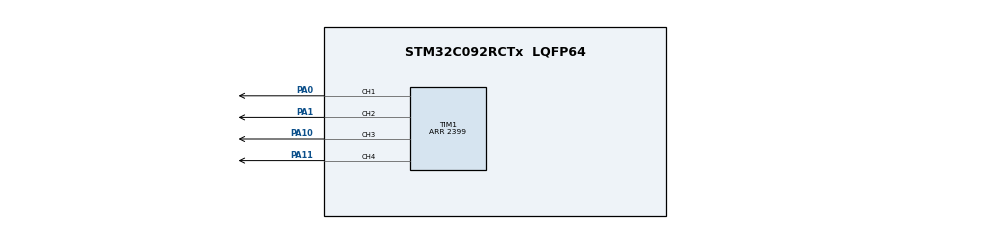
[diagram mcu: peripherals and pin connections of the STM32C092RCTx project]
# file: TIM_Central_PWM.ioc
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Mcu.Family=STM32C0
Mcu.Name=STM32C092RCTx
Mcu.Package=LQFP64
PA0.GPIO_PuPd=GPIO_PULLDOWN
PA0.GPIO_Speed=GPIO_SPEED_FREQ_HIGH
PA0.Signal=S_TIM1_CH1
PA1.GPIO_PuPd=GPIO_PULLDOWN
PA1.GPIO_Speed=GPIO_SPEED_FREQ_HIGH
PA1.Signal=S_TIM1_CH2
PA10.GPIO_PuPd=GPIO_PULLDOWN
PA10.GPIO_Speed=GPIO_SPEED_FREQ_HIGH
PA10.Signal=S_TIM1_CH3
PA11\ [PA9].GPIO_PuPd=GPIO_PULLDOWN
PA11\ [PA9].GPIO_Speed=GPIO_SPEED_FREQ_HIGH
PA11\ [PA9].Signal=S_TIM1_CH4
ProjectManager.HeapSize=0x200
ProjectManager.StackSize=0x400
ProjectManager.TargetToolchain=EWARM V9.20
RCC.ADCFreq_Value=48000000
RCC.AHBFreq_Value=48000000
RCC.CortexFreq_Value=48000000
RCC.EXTERNAL_CLOCK_VALUE=12288000
RCC.HCLKFreq_Value=48000000
RCC.HSE_VALUE=8000000
RCC.HSISYSCLKDivider=RCC_HSI_DIV1
RCC.HSI_VALUE=48000000
RCC.LSE_VALUE=32768
RCC.SYSCLKFreq_VALUE=48000000
SH.S_TIM1_CH1.0=TIM1_CH1,PWM Generation1 CH1
SH.S_TIM1_CH2.0=TIM1_CH2,PWM Generation2 CH2
SH.S_TIM1_CH3.0=TIM1_CH3,PWM Generation3 CH3
SH.S_TIM1_CH4.0=TIM1_CH4,PWM Generation4 CH4
TIM1.Channel-PWM\ Generation1\ CH1=TIM_CHANNEL_1
TIM1.Channel-PWM\ Generation2\ CH2=TIM_CHANNEL_2
TIM1.Channel-PWM\ Generation3\ CH3=TIM_CHANNEL_3
TIM1.Channel-PWM\ Generation4\ CH4=TIM_CHANNEL_4
TIM1.CounterMode=TIM_COUNTERMODE_CENTERALIGNED1
TIM1.OCMode_PWM-PWM\ Generation4\ CH4=TIM_OCMODE_PWM2
TIM1.Period=2399
TIM1.Pulse-PWM\ Generation1\ CH1=599
TIM1.Pulse-PWM\ Generation2\ CH2=1199
TIM1.Pulse-PWM\ Generation3\ CH3=1799
TIM1.Pulse-PWM\ Generation4\ CH4=2351
TIM1.TIM_MasterOutputTrigger2=TIM_TRGO2_OC4REF
VP_TIM1_VS_ClockSourceINT.Mode=Internal
board=custom

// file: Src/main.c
/* USER CODE BEGIN Header */
/**
  ******************************************************************************
  * @file           : main.c
  * @brief          : Main program body
  ******************************************************************************
  * @attention
  *
  * Copyright (c) 2024 STMicroelectronics.
  * All rights reserved.
  *
  * This software is licensed under terms that can be found in the LICENSE file
  * in the root directory of this software component.
  * If no LICENSE file comes with this software, it is provided AS-IS.
  *
  ******************************************************************************
  */
/* USER CODE END Header */
#include "main.h"

void SystemClock_Config(void);
static void MX_GPIO_Init(void);
static void MX_TIM1_Init(void);

int main(void)
{

  /* MCU Configuration--------------------------------------------------------*/

  /* Reset of all peripherals, Initializes the Flash interface and the Systick. */
  LL_APB2_GRP1_EnableClock(LL_APB2_GRP1_PERIPH_SYSCFG);
  LL_APB1_GRP1_EnableClock(LL_APB1_GRP1_PERIPH_PWR);

  /* SysTick_IRQn interrupt configuration */
  NVIC_SetPriority(SysTick_IRQn, 3);

  /* Configure the system clock */
  SystemClock_Config();

  /* Initialize all configured peripherals */
  MX_GPIO_Init();
  MX_TIM1_Init();
  /* USER CODE BEGIN 2 */

  /**********************************/
  /* Start output signal generation */
  /**********************************/
  /* Enable output channels 1, 2, 3 and 4 */
  LL_TIM_CC_EnableChannel(TIM1, LL_TIM_CHANNEL_CH1 | LL_TIM_CHANNEL_CH2 | LL_TIM_CHANNEL_CH3 | LL_TIM_CHANNEL_CH4);

  /* Enable counter */
  LL_TIM_EnableCounter(TIM1);
  /* USER CODE END 2 */

  /* Infinite loop */
  while (1)
  {

  }
}

void SystemClock_Config(void)
{

  LL_FLASH_SetLatency(LL_FLASH_LATENCY_1);

  /* HSI configuration and activation */
  LL_RCC_HSI_Enable();
  while(LL_RCC_HSI_IsReady() != 1)
  {
  }

  LL_RCC_HSI_SetCalibTrimming(64);
  LL_RCC_SetHSIDiv(LL_RCC_HSI_DIV_1);
  /* Set AHB prescaler*/
  LL_RCC_SetAHBPrescaler(LL_RCC_HCLK_DIV_1);

  LL_RCC_SetSYSDivider(LL_RCC_SYSCLK_DIV_1);
  /* Sysclk activation on the HSI */
  LL_RCC_SetSysClkSource(LL_RCC_SYS_CLKSOURCE_HSI);
  while(LL_RCC_GetSysClkSource() != LL_RCC_SYS_CLKSOURCE_STATUS_HSI)
  {
  }

  /* Set APB1 prescaler*/
  LL_RCC_SetAPB1Prescaler(LL_RCC_APB1_DIV_1);
  LL_Init1msTick(48000000);
  /* Update CMSIS variable (which can be updated also through SystemCoreClockUpdate function) */
  LL_SetSystemCoreClock(48000000);
}

static void MX_TIM1_Init(void)
{

  LL_TIM_InitTypeDef TIM_InitStruct = {0};
  LL_TIM_OC_InitTypeDef TIM_OC_InitStruct = {0};
  LL_TIM_BDTR_InitTypeDef TIM_BDTRInitStruct = {0};

  LL_GPIO_InitTypeDef GPIO_InitStruct = {0};

  /* Peripheral clock enable */
  LL_APB2_GRP1_EnableClock(LL_APB2_GRP1_PERIPH_TIM1);

  TIM_InitStruct.Prescaler = 0;
  TIM_InitStruct.CounterMode = LL_TIM_COUNTERMODE_CENTER_DOWN;
  TIM_InitStruct.Autoreload = 2399;
  TIM_InitStruct.ClockDivision = LL_TIM_CLOCKDIVISION_DIV1;
  TIM_InitStruct.RepetitionCounter = 0;
  LL_TIM_Init(TIM1, &TIM_InitStruct);
  LL_TIM_DisableARRPreload(TIM1);
  LL_TIM_SetClockSource(TIM1, LL_TIM_CLOCKSOURCE_INTERNAL);
  LL_TIM_OC_EnablePreload(TIM1, LL_TIM_CHANNEL_CH1);
  TIM_OC_InitStruct.OCMode = LL_TIM_OCMODE_PWM1;
  TIM_OC_InitStruct.OCState = LL_TIM_OCSTATE_DISABLE;
  TIM_OC_InitStruct.OCNState = LL_TIM_OCSTATE_DISABLE;
  TIM_OC_InitStruct.CompareValue = 599;
  TIM_OC_InitStruct.OCPolarity = LL_TIM_OCPOLARITY_HIGH;
  TIM_OC_InitStruct.OCNPolarity = LL_TIM_OCPOLARITY_HIGH;
  TIM_OC_InitStruct.OCIdleState = LL_TIM_OCIDLESTATE_LOW;
  TIM_OC_InitStruct.OCNIdleState = LL_TIM_OCIDLESTATE_LOW;
  LL_TIM_OC_Init(TIM1, LL_TIM_CHANNEL_CH1, &TIM_OC_InitStruct);
  LL_TIM_OC_DisableFast(TIM1, LL_TIM_CHANNEL_CH1);
  LL_TIM_OC_EnablePreload(TIM1, LL_TIM_CHANNEL_CH2);
  TIM_OC_InitStruct.CompareValue = 1199;
  LL_TIM_OC_Init(TIM1, LL_TIM_CHANNEL_CH2, &TIM_OC_InitStruct);
  LL_TIM_OC_DisableFast(TIM1, LL_TIM_CHANNEL_CH2);
  LL_TIM_OC_EnablePreload(TIM1, LL_TIM_CHANNEL_CH3);
  TIM_OC_InitStruct.CompareValue = 1799;
  LL_TIM_OC_Init(TIM1, LL_TIM_CHANNEL_CH3, &TIM_OC_InitStruct);
  LL_TIM_OC_DisableFast(TIM1, LL_TIM_CHANNEL_CH3);
  LL_TIM_OC_EnablePreload(TIM1, LL_TIM_CHANNEL_CH4);
  TIM_OC_InitStruct.OCMode = LL_TIM_OCMODE_PWM2;
  TIM_OC_InitStruct.CompareValue = 2351;
  LL_TIM_OC_Init(TIM1, LL_TIM_CHANNEL_CH4, &TIM_OC_InitStruct);
  LL_TIM_OC_DisableFast(TIM1, LL_TIM_CHANNEL_CH4);
  LL_TIM_SetTriggerOutput(TIM1, LL_TIM_TRGO_RESET);
  LL_TIM_SetTriggerOutput2(TIM1, LL_TIM_TRGO2_OC4);
  LL_TIM_DisableMasterSlaveMode(TIM1);
  TIM_BDTRInitStruct.OSSRState = LL_TIM_OSSR_DISABLE;
  TIM_BDTRInitStruct.OSSIState = LL_TIM_OSSI_DISABLE;
  TIM_BDTRInitStruct.LockLevel = LL_TIM_LOCKLEVEL_OFF;
  TIM_BDTRInitStruct.DeadTime = 0;
  TIM_BDTRInitStruct.BreakState = LL_TIM_BREAK_DISABLE;
  TIM_BDTRInitStruct.BreakPolarity = LL_TIM_BREAK_POLARITY_HIGH;
  TIM_BDTRInitStruct.BreakFilter = LL_TIM_BREAK_FILTER_FDIV1;
  TIM_BDTRInitStruct.BreakAFMode = LL_TIM_BREAK_AFMODE_INPUT;
  TIM_BDTRInitStruct.Break2State = LL_TIM_BREAK2_DISABLE;
  TIM_BDTRInitStruct.Break2Polarity = LL_TIM_BREAK2_POLARITY_HIGH;
  TIM_BDTRInitStruct.Break2Filter = LL_TIM_BREAK2_FILTER_FDIV1;
  TIM_BDTRInitStruct.Break2AFMode = LL_TIM_BREAK_AFMODE_INPUT;
  TIM_BDTRInitStruct.AutomaticOutput = LL_TIM_AUTOMATICOUTPUT_DISABLE;
  LL_TIM_BDTR_Init(TIM1, &TIM_BDTRInitStruct);
  /* USER CODE BEGIN TIM1_Init 2 */

  /* Enable the outputs */
  LL_TIM_EnableAllOutputs(TIM1);

  /* USER CODE END TIM1_Init 2 */
  LL_IOP_GRP1_EnableClock(LL_IOP_GRP1_PERIPH_GPIOA);
  /**TIM1 GPIO Configuration
  PA0   ------> TIM1_CH1
  PA1   ------> TIM1_CH2
  PA10   ------> TIM1_CH3
  PA11 [PA9]   ------> TIM1_CH4
  */
  GPIO_InitStruct.Pin = LL_GPIO_PIN_0;
  GPIO_InitStruct.Mode = LL_GPIO_MODE_ALTERNATE;
  GPIO_InitStruct.Speed = LL_GPIO_SPEED_FREQ_HIGH;
  GPIO_InitStruct.OutputType = LL_GPIO_OUTPUT_PUSHPULL;
  GPIO_InitStruct.Pull = LL_GPIO_PULL_DOWN;
  GPIO_InitStruct.Alternate = LL_GPIO_AF_5;
  LL_GPIO_Init(GPIOA, &GPIO_InitStruct);

  GPIO_InitStruct.Pin = LL_GPIO_PIN_1;
  GPIO_InitStruct.Mode = LL_GPIO_MODE_ALTERNATE;
  GPIO_InitStruct.Speed = LL_GPIO_SPEED_FREQ_HIGH;
  GPIO_InitStruct.OutputType = LL_GPIO_OUTPUT_PUSHPULL;
  GPIO_InitStruct.Pull = LL_GPIO_PULL_DOWN;
  GPIO_InitStruct.Alternate = LL_GPIO_AF_5;
  LL_GPIO_Init(GPIOA, &GPIO_InitStruct);

  GPIO_InitStruct.Pin = LL_GPIO_PIN_10;
  GPIO_InitStruct.Mode = LL_GPIO_MODE_ALTERNATE;
  GPIO_InitStruct.Speed = LL_GPIO_SPEED_FREQ_HIGH;
  GPIO_InitStruct.OutputType = LL_GPIO_OUTPUT_PUSHPULL;
  GPIO_InitStruct.Pull = LL_GPIO_PULL_DOWN;
  GPIO_InitStruct.Alternate = LL_GPIO_AF_2;
  LL_GPIO_Init(GPIOA, &GPIO_InitStruct);

  GPIO_InitStruct.Pin = LL_GPIO_PIN_11;
  GPIO_InitStruct.Mode = LL_GPIO_MODE_ALTERNATE;
  GPIO_InitStruct.Speed = LL_GPIO_SPEED_FREQ_HIGH;
  GPIO_InitStruct.OutputType = LL_GPIO_OUTPUT_PUSHPULL;
  GPIO_InitStruct.Pull = LL_GPIO_PULL_DOWN;
  GPIO_InitStruct.Alternate = LL_GPIO_AF_2;
  LL_GPIO_Init(GPIOA, &GPIO_InitStruct);

}

static void MX_GPIO_Init(void)
{

  /* GPIO Ports Clock Enable */
  LL_IOP_GRP1_EnableClock(LL_IOP_GRP1_PERIPH_GPIOA);

}

void Error_Handler(void)
{
  __disable_irq();
  while (1)
  {
  }
}
